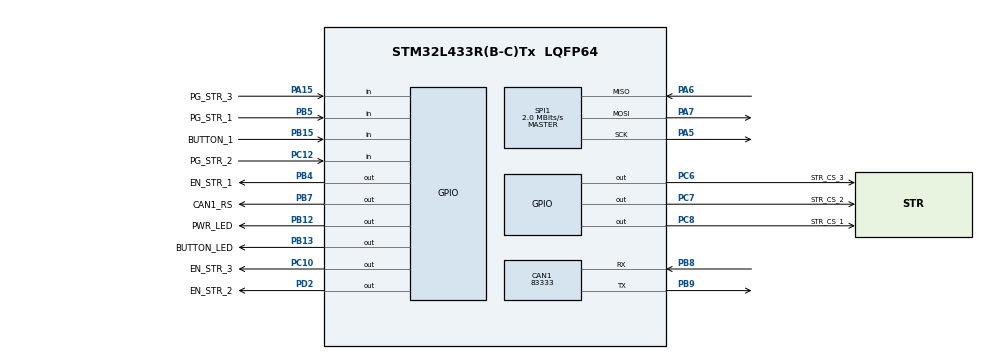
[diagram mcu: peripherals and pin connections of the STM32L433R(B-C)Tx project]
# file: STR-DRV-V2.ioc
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CAN1.CalculateBaudRate=83333
CAN1.CalculateTimeBit=12000
CAN1.CalculateTimeQuantum=4000.0
Mcu.Family=STM32L4
Mcu.Name=STM32L433R(B-C)Tx
Mcu.Package=LQFP64
NVIC.PriorityGroup=NVIC_PRIORITYGROUP_4
PA0.GPIO_Label=STR_ADC_3
PA0.Signal=ADCx_IN5
PA1.GPIO_Label=NTC_READ
PA1.Signal=ADCx_IN6
PA13\ (JTMS-SWDIO).GPIO_Label=SWDIO
PA13\ (JTMS-SWDIO).Signal=SYS_JTMS-SWDIO
PA14\ (JTCK-SWCLK).GPIO_Label=SWCLK
PA14\ (JTCK-SWCLK).Signal=SYS_JTCK-SWCLK
PA15\ (JTDI).GPIO_Label=PG_STR_3
PA15\ (JTDI).GPIO_PuPd=GPIO_PULLUP
PA15\ (JTDI).Signal=GPIO_Input
PA5.Mode=Full_Duplex_Master
PA5.Signal=SPI1_SCK
PA6.Mode=Full_Duplex_Master
PA6.Signal=SPI1_MISO
PA7.Mode=Full_Duplex_Master
PA7.Signal=SPI1_MOSI
PB12.GPIO_Label=PWR_LED
PB12.GPIO_PuPd=GPIO_PULLDOWN
PB12.Signal=GPIO_Output
PB13.GPIO_Label=BUTTON_LED
PB13.GPIO_PuPd=GPIO_PULLDOWN
PB13.Signal=GPIO_Output
PB15.GPIO_Label=BUTTON_1
PB15.GPIO_PuPd=GPIO_PULLDOWN
PB15.Signal=GPIO_Input
PB4\ (NJTRST).GPIO_Label=EN_STR_1
PB4\ (NJTRST).GPIO_PuPd=GPIO_PULLDOWN
PB4\ (NJTRST).Signal=GPIO_Output
PB5.GPIO_Label=PG_STR_1
PB5.GPIO_PuPd=GPIO_PULLUP
PB5.Signal=GPIO_Input
PB7.GPIO_Label=CAN1_RS
PB7.Signal=GPIO_Output
PB8.Mode=CAN_Activate
PB8.Signal=CAN1_RX
PB9.Mode=CAN_Activate
PB9.Signal=CAN1_TX
PC0.GPIO_Label=DBG_RX
PC0.Signal=LPUART1_RX
PC1.GPIO_Label=DBG_TX
PC1.Signal=LPUART1_TX
PC10.GPIO_Label=EN_STR_3
PC10.GPIO_PuPd=GPIO_PULLDOWN
PC10.Signal=GPIO_Output
PC12.GPIO_Label=PG_STR_2
PC12.GPIO_PuPd=GPIO_PULLUP
PC12.Signal=GPIO_Input
PC14-OSC32_IN\ (PC14).Mode=LSE-External-Oscillator
PC14-OSC32_IN\ (PC14).Signal=RCC_OSC32_IN
PC15-OSC32_OUT\ (PC15).Mode=LSE-External-Oscillator
PC15-OSC32_OUT\ (PC15).Signal=RCC_OSC32_OUT
PC2.GPIO_Label=STR_ADC_1
PC2.Signal=ADCx_IN3
PC3.GPIO_Label=STR_ADC_2
PC3.Signal=ADCx_IN4
PC6.GPIO_Label=STR_CS_3
PC6.GPIO_PuPd=GPIO_PULLUP
PC6.GPIO_Speed=GPIO_SPEED_FREQ_VERY_HIGH
PC6.Signal=GPIO_Output
PC7.GPIO_Label=STR_CS_2
PC7.GPIO_PuPd=GPIO_PULLUP
PC7.GPIO_Speed=GPIO_SPEED_FREQ_VERY_HIGH
PC7.Signal=GPIO_Output
PC8.GPIO_Label=STR_CS_1
PC8.GPIO_PuPd=GPIO_PULLUP
PC8.GPIO_Speed=GPIO_SPEED_FREQ_VERY_HIGH
PC8.Signal=GPIO_Output
PD2.GPIO_Label=EN_STR_2
PD2.GPIO_PuPd=GPIO_PULLDOWN
PD2.Signal=GPIO_Output
ProjectManager.HeapSize=0x200
ProjectManager.StackSize=0x400
ProjectManager.TargetToolchain=CMake
RCC.HSE_VALUE=8000000
RCC.HSI48_VALUE=48000000
RCC.HSI_VALUE=16000000
RCC.MSI_VALUE=4000000
RCC.VCOOutputFreq_Value=32000000
SH.ADCx_IN3.0=ADC1_IN3
SH.ADCx_IN4.0=ADC1_IN4
SH.ADCx_IN5.0=ADC1_IN5
SH.ADCx_IN6.0=ADC1_IN6
SPI1.BaudRatePrescaler=SPI_BAUDRATEPRESCALER_2
SPI1.CalculateBaudRate=2.0 MBits/s
SPI1.DataSize=SPI_DATASIZE_8BIT
SPI1.Direction=SPI_DIRECTION_2LINES
SPI1.Mode=SPI_MODE_MASTER
SPI1.VirtualType=VM_MASTER
board=custom

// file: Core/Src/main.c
/* USER CODE BEGIN Header */
/**
  ******************************************************************************
  * @file           : main.c
  * @brief          : Main program body
  ******************************************************************************
  * @attention
  *
  * Copyright (c) 2025 STMicroelectronics.
  * All rights reserved.
  *
  * This software is licensed under terms that can be found in the LICENSE file
  * in the root directory of this software component.
  * If no LICENSE file comes with this software, it is provided AS-IS.
  *
  ******************************************************************************
  */
/* USER CODE END Header */
#include "main.h"

CAN_HandleTypeDef hcan1;

SPI_HandleTypeDef hspi1;

void SystemClock_Config(void);
static void MX_GPIO_Init(void);
static void MX_CAN1_Init(void);
static void MX_SPI1_Init(void);
static void SetPotentiometerValue(SPI_HandleTypeDef *hspi, uint8_t value, uint8_t lampada);

int main(void)
{

  /* MCU Configuration--------------------------------------------------------*/

  /* Reset of all peripherals, Initializes the Flash interface and the Systick. */
  HAL_Init();

  /* Configure the system clock */
  SystemClock_Config();

  /* Initialize all configured peripherals */
  MX_GPIO_Init();
  MX_CAN1_Init();
  MX_SPI1_Init();

  /* Infinite loop */
  /* USER CODE BEGIN WHILE */

  HAL_GPIO_WritePin(PWR_LED_GPIO_Port, PWR_LED_Pin, GPIO_PIN_SET); // Turn on power LED
  //Turn on enables
  HAL_GPIO_WritePin(EN_STR_1_GPIO_Port, EN_STR_1_Pin, GPIO_PIN_SET);
  HAL_GPIO_WritePin(EN_STR_2_GPIO_Port, EN_STR_2_Pin, GPIO_PIN_SET);
  HAL_GPIO_WritePin(EN_STR_3_GPIO_Port, EN_STR_3_Pin, GPIO_PIN_SET);

  SetPotentiometerValue(&hspi1,0,1);
  SetPotentiometerValue(&hspi1,0,2);
  SetPotentiometerValue(&hspi1,0,3);

  while (1)
  {
    /* USER CODE END WHILE */
    HAL_GPIO_TogglePin(BUTTON_LED_GPIO_Port, BUTTON_LED_Pin);
    HAL_Delay(500); // Toggle every 500 ms
  }
}

void SetPotentiometerValue(SPI_HandleTypeDef *hspi, uint8_t value, uint8_t lampada) {
    uint8_t command = 0x11; // Comando per scrivere nel potenziometro
    uint8_t data[2] = {command, value};

    // Porta NSS bassa per selezionare il dispositivo
    if (lampada == 1)
    {

    	HAL_GPIO_WritePin(GPIOC, GPIO_PIN_8, GPIO_PIN_RESET);

    }
    else if (lampada == 2)
    {

    	HAL_GPIO_WritePin(GPIOC, GPIO_PIN_7, GPIO_PIN_RESET);

    }

    else if (lampada == 3)
	{

		HAL_GPIO_WritePin(GPIOC, GPIO_PIN_6, GPIO_PIN_RESET);

	}

    // Invia i dati tramite SPI
    HAL_SPI_Transmit(hspi, data, 2, HAL_MAX_DELAY);

    // Porta NSS alta per deselezionare il dispositivo
    if (lampada == 1)
    {

    	HAL_GPIO_WritePin(GPIOC, GPIO_PIN_8, GPIO_PIN_SET);

    }
    else if (lampada == 2)
    {

    	HAL_GPIO_WritePin(GPIOC, GPIO_PIN_7, GPIO_PIN_SET);

    }

    else if (lampada == 3)
	{

		HAL_GPIO_WritePin(GPIOC, GPIO_PIN_6, GPIO_PIN_SET);

	}
}

void SystemClock_Config(void)
{
  RCC_OscInitTypeDef RCC_OscInitStruct = {0};
  RCC_ClkInitTypeDef RCC_ClkInitStruct = {0};

  /** Configure the main internal regulator output voltage
  */
  if (HAL_PWREx_ControlVoltageScaling(PWR_REGULATOR_VOLTAGE_SCALE1) != HAL_OK)
  {
    Error_Handler();
  }

  /** Configure LSE Drive Capability
  */
  HAL_PWR_EnableBkUpAccess();
  __HAL_RCC_LSEDRIVE_CONFIG(RCC_LSEDRIVE_LOW);

  /** Initializes the RCC Oscillators according to the specified parameters
  * in the RCC_OscInitTypeDef structure.
  */
  RCC_OscInitStruct.OscillatorType = RCC_OSCILLATORTYPE_LSE|RCC_OSCILLATORTYPE_MSI;
  RCC_OscInitStruct.LSEState = RCC_LSE_ON;
  RCC_OscInitStruct.MSIState = RCC_MSI_ON;
  RCC_OscInitStruct.MSICalibrationValue = 0;
  RCC_OscInitStruct.MSIClockRange = RCC_MSIRANGE_6;
  RCC_OscInitStruct.PLL.PLLState = RCC_PLL_NONE;
  if (HAL_RCC_OscConfig(&RCC_OscInitStruct) != HAL_OK)
  {
    Error_Handler();
  }

  /** Initializes the CPU, AHB and APB buses clocks
  */
  RCC_ClkInitStruct.ClockType = RCC_CLOCKTYPE_HCLK|RCC_CLOCKTYPE_SYSCLK
                              |RCC_CLOCKTYPE_PCLK1|RCC_CLOCKTYPE_PCLK2;
  RCC_ClkInitStruct.SYSCLKSource = RCC_SYSCLKSOURCE_MSI;
  RCC_ClkInitStruct.AHBCLKDivider = RCC_SYSCLK_DIV1;
  RCC_ClkInitStruct.APB1CLKDivider = RCC_HCLK_DIV1;
  RCC_ClkInitStruct.APB2CLKDivider = RCC_HCLK_DIV1;

  if (HAL_RCC_ClockConfig(&RCC_ClkInitStruct, FLASH_LATENCY_0) != HAL_OK)
  {
    Error_Handler();
  }

  /** Enable MSI Auto calibration
  */
  HAL_RCCEx_EnableMSIPLLMode();
}

static void MX_CAN1_Init(void)
{

  hcan1.Instance = CAN1;
  hcan1.Init.Prescaler = 16;
  hcan1.Init.Mode = CAN_MODE_NORMAL;
  hcan1.Init.SyncJumpWidth = CAN_SJW_1TQ;
  hcan1.Init.TimeSeg1 = CAN_BS1_1TQ;
  hcan1.Init.TimeSeg2 = CAN_BS2_1TQ;
  hcan1.Init.TimeTriggeredMode = DISABLE;
  hcan1.Init.AutoBusOff = DISABLE;
  hcan1.Init.AutoWakeUp = DISABLE;
  hcan1.Init.AutoRetransmission = DISABLE;
  hcan1.Init.ReceiveFifoLocked = DISABLE;
  hcan1.Init.TransmitFifoPriority = DISABLE;
  if (HAL_CAN_Init(&hcan1) != HAL_OK)
  {
    Error_Handler();
  }

}

static void MX_SPI1_Init(void)
{

  /* SPI1 parameter configuration*/
  hspi1.Instance = SPI1;
  hspi1.Init.Mode = SPI_MODE_MASTER;
  hspi1.Init.Direction = SPI_DIRECTION_2LINES;
  hspi1.Init.DataSize = SPI_DATASIZE_8BIT;
  hspi1.Init.CLKPolarity = SPI_POLARITY_LOW;
  hspi1.Init.CLKPhase = SPI_PHASE_1EDGE;
  hspi1.Init.NSS = SPI_NSS_SOFT;
  hspi1.Init.BaudRatePrescaler = SPI_BAUDRATEPRESCALER_2;
  hspi1.Init.FirstBit = SPI_FIRSTBIT_MSB;
  hspi1.Init.TIMode = SPI_TIMODE_DISABLE;
  hspi1.Init.CRCCalculation = SPI_CRCCALCULATION_DISABLE;
  hspi1.Init.CRCPolynomial = 7;
  hspi1.Init.CRCLength = SPI_CRC_LENGTH_DATASIZE;
  hspi1.Init.NSSPMode = SPI_NSS_PULSE_ENABLE;
  if (HAL_SPI_Init(&hspi1) != HAL_OK)
  {
    Error_Handler();
  }

}

static void MX_GPIO_Init(void)
{
  GPIO_InitTypeDef GPIO_InitStruct = {0};

  /* GPIO Ports Clock Enable */
  __HAL_RCC_GPIOC_CLK_ENABLE();
  __HAL_RCC_GPIOA_CLK_ENABLE();
  __HAL_RCC_GPIOB_CLK_ENABLE();
  __HAL_RCC_GPIOD_CLK_ENABLE();

  /*Configure GPIO pin Output Level */
  HAL_GPIO_WritePin(GPIOB, PWR_LED_Pin|BUTTON_LED_Pin|EN_STR_1_Pin|CAN1_RS_Pin, GPIO_PIN_RESET);

  /*Configure GPIO pin Output Level */
  HAL_GPIO_WritePin(GPIOC, STR_CS_3_Pin|STR_CS_2_Pin|STR_CS_1_Pin|EN_STR_3_Pin, GPIO_PIN_RESET);

  /*Configure GPIO pin Output Level */
  HAL_GPIO_WritePin(EN_STR_2_GPIO_Port, EN_STR_2_Pin, GPIO_PIN_RESET);

  /*Configure GPIO pins : DBG_RX_Pin DBG_TX_Pin */
  GPIO_InitStruct.Pin = DBG_RX_Pin|DBG_TX_Pin;
  GPIO_InitStruct.Mode = GPIO_MODE_AF_PP;
  GPIO_InitStruct.Pull = GPIO_NOPULL;
  GPIO_InitStruct.Speed = GPIO_SPEED_FREQ_VERY_HIGH;
  GPIO_InitStruct.Alternate = GPIO_AF8_LPUART1;
  HAL_GPIO_Init(GPIOC, &GPIO_InitStruct);

  /*Configure GPIO pins : STR_ADC_1_Pin STR_ADC_2_Pin */
  GPIO_InitStruct.Pin = STR_ADC_1_Pin|STR_ADC_2_Pin;
  GPIO_InitStruct.Mode = GPIO_MODE_ANALOG_ADC_CONTROL;
  GPIO_InitStruct.Pull = GPIO_NOPULL;
  HAL_GPIO_Init(GPIOC, &GPIO_InitStruct);

  /*Configure GPIO pins : STR_ADC_3_Pin NTC_READ_Pin */
  GPIO_InitStruct.Pin = STR_ADC_3_Pin|NTC_READ_Pin;
  GPIO_InitStruct.Mode = GPIO_MODE_ANALOG_ADC_CONTROL;
  GPIO_InitStruct.Pull = GPIO_NOPULL;
  HAL_GPIO_Init(GPIOA, &GPIO_InitStruct);

  /*Configure GPIO pins : PWR_LED_Pin BUTTON_LED_Pin EN_STR_1_Pin */
  GPIO_InitStruct.Pin = PWR_LED_Pin|BUTTON_LED_Pin|EN_STR_1_Pin;
  GPIO_InitStruct.Mode = GPIO_MODE_OUTPUT_PP;
  GPIO_InitStruct.Pull = GPIO_PULLDOWN;
  GPIO_InitStruct.Speed = GPIO_SPEED_FREQ_LOW;
  HAL_GPIO_Init(GPIOB, &GPIO_InitStruct);

  /*Configure GPIO pin : BUTTON_1_Pin */
  GPIO_InitStruct.Pin = BUTTON_1_Pin;
  GPIO_InitStruct.Mode = GPIO_MODE_INPUT;
  GPIO_InitStruct.Pull = GPIO_PULLDOWN;
  HAL_GPIO_Init(BUTTON_1_GPIO_Port, &GPIO_InitStruct);

  /*Configure GPIO pins : STR_CS_3_Pin STR_CS_2_Pin STR_CS_1_Pin */
  GPIO_InitStruct.Pin = STR_CS_3_Pin|STR_CS_2_Pin|STR_CS_1_Pin;
  GPIO_InitStruct.Mode = GPIO_MODE_OUTPUT_PP;
  GPIO_InitStruct.Pull = GPIO_PULLUP;
  GPIO_InitStruct.Speed = GPIO_SPEED_FREQ_VERY_HIGH;
  HAL_GPIO_Init(GPIOC, &GPIO_InitStruct);

  /*Configure GPIO pin : PG_STR_3_Pin */
  GPIO_InitStruct.Pin = PG_STR_3_Pin;
  GPIO_InitStruct.Mode = GPIO_MODE_INPUT;
  GPIO_InitStruct.Pull = GPIO_PULLUP;
  HAL_GPIO_Init(PG_STR_3_GPIO_Port, &GPIO_InitStruct);

  /*Configure GPIO pin : EN_STR_3_Pin */
  GPIO_InitStruct.Pin = EN_STR_3_Pin;
  GPIO_InitStruct.Mode = GPIO_MODE_OUTPUT_PP;
  GPIO_InitStruct.Pull = GPIO_PULLDOWN;
  GPIO_InitStruct.Speed = GPIO_SPEED_FREQ_LOW;
  HAL_GPIO_Init(EN_STR_3_GPIO_Port, &GPIO_InitStruct);

  /*Configure GPIO pin : PG_STR_2_Pin */
  GPIO_InitStruct.Pin = PG_STR_2_Pin;
  GPIO_InitStruct.Mode = GPIO_MODE_INPUT;
  GPIO_InitStruct.Pull = GPIO_PULLUP;
  HAL_GPIO_Init(PG_STR_2_GPIO_Port, &GPIO_InitStruct);

  /*Configure GPIO pin : EN_STR_2_Pin */
  GPIO_InitStruct.Pin = EN_STR_2_Pin;
  GPIO_InitStruct.Mode = GPIO_MODE_OUTPUT_PP;
  GPIO_InitStruct.Pull = GPIO_PULLDOWN;
  GPIO_InitStruct.Speed = GPIO_SPEED_FREQ_LOW;
  HAL_GPIO_Init(EN_STR_2_GPIO_Port, &GPIO_InitStruct);

  /*Configure GPIO pin : PG_STR_1_Pin */
  GPIO_InitStruct.Pin = PG_STR_1_Pin;
  GPIO_InitStruct.Mode = GPIO_MODE_INPUT;
  GPIO_InitStruct.Pull = GPIO_PULLUP;
  HAL_GPIO_Init(PG_STR_1_GPIO_Port, &GPIO_InitStruct);

  /*Configure GPIO pin : CAN1_RS_Pin */
  GPIO_InitStruct.Pin = CAN1_RS_Pin;
  GPIO_InitStruct.Mode = GPIO_MODE_OUTPUT_PP;
  GPIO_InitStruct.Pull = GPIO_NOPULL;
  GPIO_InitStruct.Speed = GPIO_SPEED_FREQ_LOW;
  HAL_GPIO_Init(CAN1_RS_GPIO_Port, &GPIO_InitStruct);

}

void Error_Handler(void)
{
  __disable_irq();
  while (1)
  {
  }
}
